# HC32F558 register map
File version: 1.0
CPU: CM4 r0p1, little endian, MPU, FPU, 4 interrupt priority bits
Registers are 32-bit, read-write, reset 0x0 unless marked. A register's access mark holds for its fields unless they carry their own. Offsets are from the block's base; [hi:lo] are bit positions; {n}, {i} and the like mark numbered series.

## CRC
Base 0x40008C00
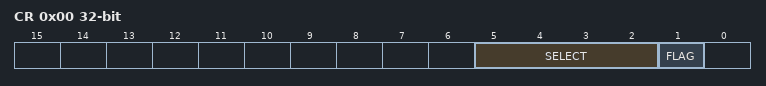
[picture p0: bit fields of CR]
0x00 CR
  [5:2] SELECT, [1] FLAG ro
0x04 RESLT
{0x80+4i} DAT{i} wo (i=0..31)

## CTC
Base 0x40049C00
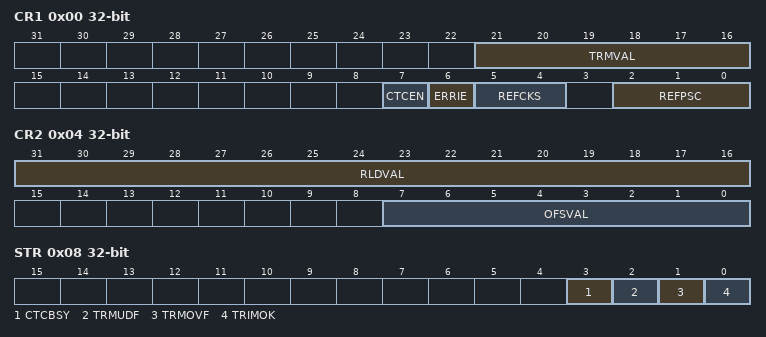
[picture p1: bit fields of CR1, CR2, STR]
0x00 CR1
  [21:16] TRMVAL, [7] CTCEN, [6] ERRIE, [5:4] REFCKS, [2:0] REFPSC
0x04 CR2
  [31:16] RLDVAL, [7:0] OFSVAL
0x08 STR ro
  [3] CTCBSY, [2] TRMUDF, [1] TRMOVF, [0] TRIMOK

## DAC1 — desc DAC
Base 0x40041000
Same registers: DAC2 0x40041400, DAC3 0x40041800, DAC4 0x40041C00
0x00 DADR1 16-bit
0x02 DADR2 16-bit
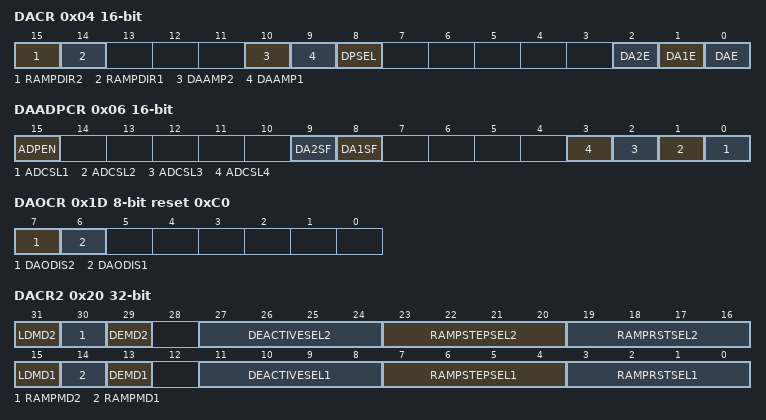
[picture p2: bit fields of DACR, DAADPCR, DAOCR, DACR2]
0x04 DACR 16-bit
  [15] RAMPDIR2, [14] RAMPDIR1, [10] DAAMP2, [9] DAAMP1, [8] DPSEL, [2] DA2E, [1] DA1E, [0] DAE
0x06 DAADPCR 16-bit
  [15] ADPEN, [9] DA2SF ro, [8] DA1SF ro, [n-1] ADCSL{n} (n=1..4)
0x1D DAOCR 8-bit reset 0xC0
  [7] DAODIS2, [6] DAODIS1
0x20 DACR2
  [31] LDMD2, [30] RAMPMD2, [29] DEMD2, [27:24] DEACTIVESEL2, [23:20] RAMPSTEPSEL2, [19:16] RAMPRSTSEL2, [15] LDMD1, [14] RAMPMD1, [13] DEMD1, [11:8] DEACTIVESEL1, [7:4] RAMPSTEPSEL1, [3:0] RAMPRSTSEL1
0x24 RAMPLMTR1 16-bit
  [11:0] RAMPLMT
0x26 RAMPLMTR2 16-bit
  [11:0] RAMPLMT
0x28 RAMPSTEPR1 16-bit
  [11:0] RAMPSTEP
0x2A RAMPSTEPR2 16-bit
  [11:0] RAMPSTEP
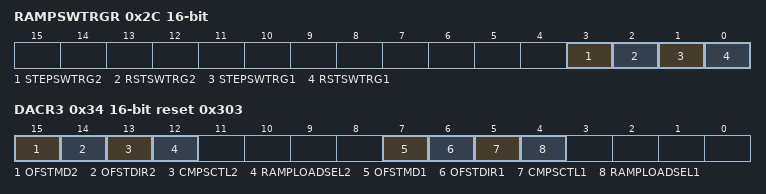
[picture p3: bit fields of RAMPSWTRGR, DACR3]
0x2C RAMPSWTRGR 16-bit wo
  [3] STEPSWTRG2, [2] RSTSWTRG2, [1] STEPSWTRG1, [0] RSTSWTRG1
0x30 DADACTR1 16-bit ro
  [11:0] DATAACT
0x32 DADACTR2 16-bit ro
  [11:0] DATAACT
0x34 DACR3 16-bit reset 0x303
  [15] OFSTMD2, [14] OFSTDIR2, [13] CMPSCTL2, [12] RAMPLOADSEL2, [7] OFSTMD1, [6] OFSTDIR1, [5] CMPSCTL1, [4] RAMPLOADSEL1
0x38 DADRDE1 16-bit
0x3A DADRDE2 16-bit
0x3C DADROF1 16-bit
0x3E DADROF2 16-bit
0x4C RAMPRSTDLYR1 16-bit
  [11:0] DARAMPRSTDLY
0x4E RAMPRSTDLYR2 16-bit
  [11:0] DARAMPRSTDLY
0x50 RAMPLMTACTR1 16-bit
  [11:0] RAMPLMTACT
0x52 RAMPLMTACTR2 16-bit
  [11:0] RAMPLMTACT
0x54 RAMPSTEPACTR1 16-bit
  [11:0] RAMPSTEPACT
0x56 RAMPSTEPACTR2 16-bit
  [11:0] RAMPSTEPACT
0x58 RAMPRSTDLYACTR1 16-bit
  [11:0] DARAMPRSTDLYACT
0x5A RAMPRSTDLYACTR2 16-bit
  [11:0] DARAMPRSTDLYACT

## DBGC
Base 0xE0042000
{0x0+4i} AUTHID{i} (i=0..2)
0x0C CHIPID ro reset 0x58480558
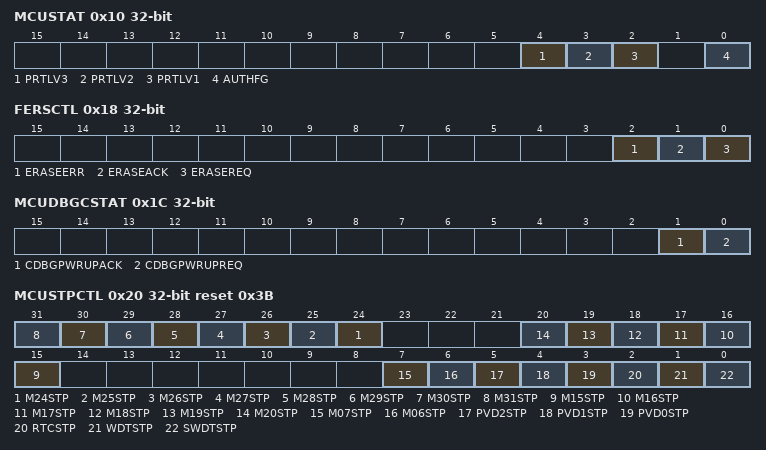
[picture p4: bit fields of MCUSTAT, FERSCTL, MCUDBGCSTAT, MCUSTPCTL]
0x10 MCUSTAT
  [4] PRTLV3, [3] PRTLV2, [2] PRTLV1, [0] AUTHFG
0x18 FERSCTL
  [2] ERASEERR, [1] ERASEACK, [0] ERASEREQ
0x1C MCUDBGCSTAT
  [1] CDBGPWRUPACK, [0] CDBGPWRUPREQ
0x20 MCUSTPCTL reset 0x3B (reset mask 0xFF1FF80FF)
  [n] M{n}STP (n=24..31), [n] M{n}STP (n=15..20), [7] M07STP, [6] M06STP, [5] PVD2STP, [4] PVD1STP, [3] PVD0STP, [2] RTCSTP, [1] WDTSTP, [0] SWDTSTP
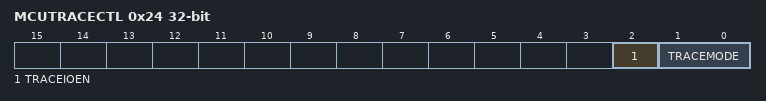
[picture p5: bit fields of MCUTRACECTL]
0x24 MCUTRACECTL
  [2] TRACEIOEN, [1:0] TRACEMODE

## DMA1 — desc DMA
Base 0x40053000
Same registers: DMA2 0x40053400
0x00 EN
  [0] EN
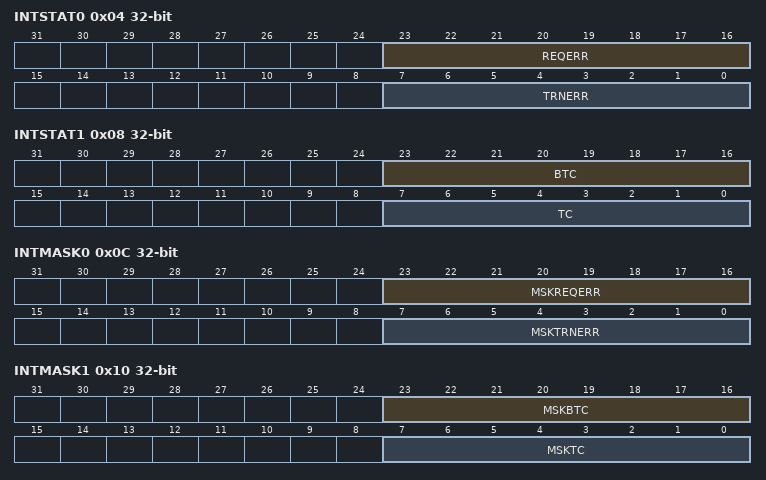
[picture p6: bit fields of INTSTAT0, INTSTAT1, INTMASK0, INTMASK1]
0x04 INTSTAT0 ro
  [23:16] REQERR, [7:0] TRNERR
0x08 INTSTAT1 ro
  [23:16] BTC, [7:0] TC
0x0C INTMASK0
  [23:16] MSKREQERR, [7:0] MSKTRNERR
0x10 INTMASK1
  [23:16] MSKBTC, [7:0] MSKTC
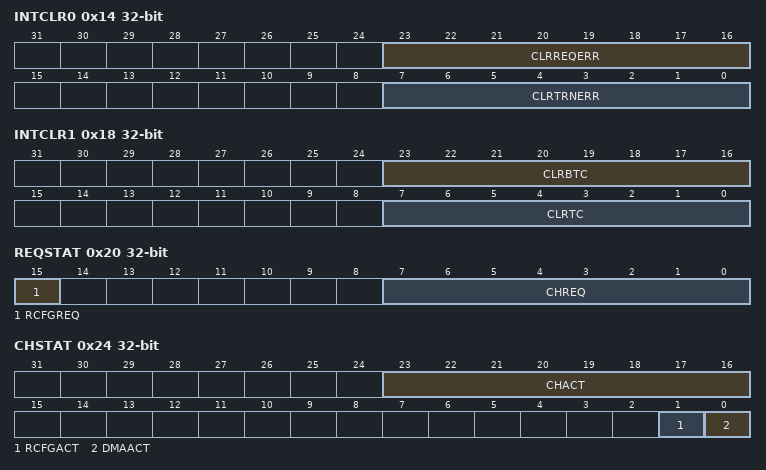
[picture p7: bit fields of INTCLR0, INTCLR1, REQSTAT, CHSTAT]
0x14 INTCLR0
  [23:16] CLRREQERR, [7:0] CLRTRNERR
0x18 INTCLR1
  [23:16] CLRBTC, [7:0] CLRTC
0x1C CHEN
  [7:0] CHEN
0x20 REQSTAT ro
  [15] RCFGREQ, [7:0] CHREQ
0x24 CHSTAT ro
  [23:16] CHACT, [1] RCFGACT, [0] DMAACT
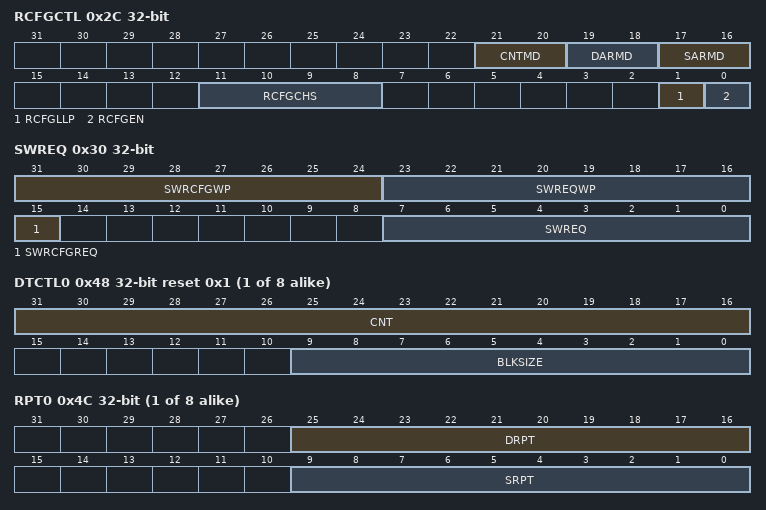
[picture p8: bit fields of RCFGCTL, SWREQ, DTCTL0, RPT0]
0x2C RCFGCTL
  [21:20] CNTMD, [19:18] DARMD, [17:16] SARMD, [11:8] RCFGCHS, [1] RCFGLLP, [0] RCFGEN
0x30 SWREQ wo
  [31:24] SWRCFGWP, [23:16] SWREQWP, [15] SWRCFGREQ, [7:0] SWREQ
0x34 CHENCLR wo
  [7:0] CHENCLR
{0x40+0x40*i} SAR{i} (i=0..7)
{0x44+0x40*i} DAR{i} (i=0..7)
{0x48+0x40*i} DTCTL{i} reset 0x1 (i=0..7)
  [31:16] CNT, [9:0] BLKSIZE
{0x4C+0x40*i} RPT{i} (i=0..7)
  [25:16] DRPT, [9:0] SRPT
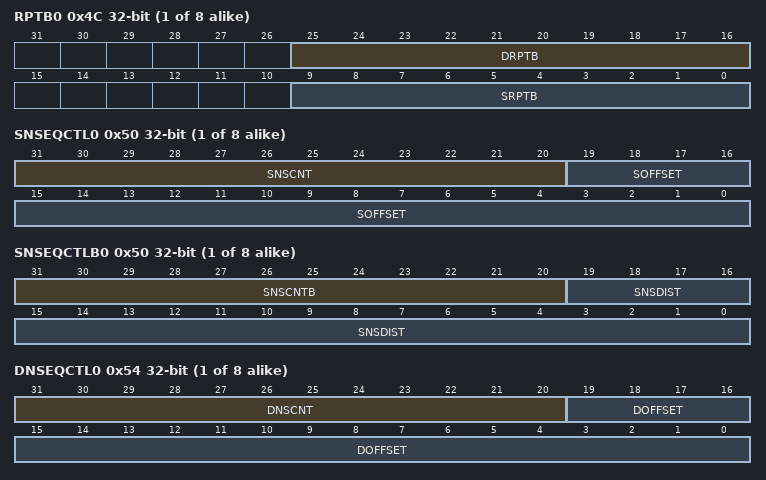
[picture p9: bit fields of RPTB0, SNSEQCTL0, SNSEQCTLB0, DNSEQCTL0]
{0x4C+0x40*i} RPTB{i} (alternate view of RPT{i}) (i=0..7)
  [25:16] DRPTB, [9:0] SRPTB
{0x50+0x40*i} SNSEQCTL{i} (i=0..7)
  [31:20] SNSCNT, [19:0] SOFFSET
{0x50+0x40*i} SNSEQCTLB{i} (alternate view of SNSEQCTL{i}) (i=0..7)
  [31:20] SNSCNTB, [19:0] SNSDIST
{0x54+0x40*i} DNSEQCTL{i} (i=0..7)
  [31:20] DNSCNT, [19:0] DOFFSET
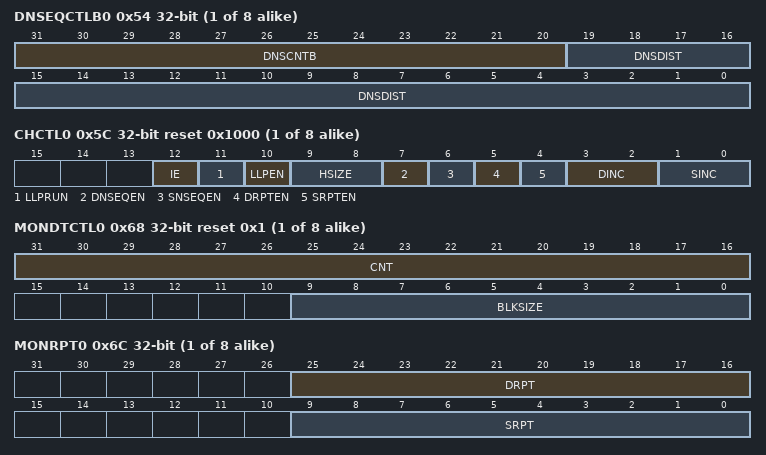
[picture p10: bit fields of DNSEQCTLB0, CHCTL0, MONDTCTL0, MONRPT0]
{0x54+0x40*i} DNSEQCTLB{i} (alternate view of DNSEQCTL{i}) (i=0..7)
  [31:20] DNSCNTB, [19:0] DNSDIST
{0x58+0x40*i} LLP{i} (i=0..7)
  [31:2] LLP
{0x5C+0x40*i} CHCTL{i} reset 0x1000 (i=0..7)
  [12] IE, [11] LLPRUN, [10] LLPEN, [9:8] HSIZE, [7] DNSEQEN, [6] SNSEQEN, [5] DRPTEN, [4] SRPTEN, [3:2] DINC, [1:0] SINC
{0x60+0x40*i} MONSAR{i} ro (i=0..7)
{0x64+0x40*i} MONDAR{i} ro (i=0..7)
{0x68+0x40*i} MONDTCTL{i} ro reset 0x1 (i=0..7)
  [31:16] CNT, [9:0] BLKSIZE
{0x6C+0x40*i} MONRPT{i} ro (i=0..7)
  [25:16] DRPT, [9:0] SRPT
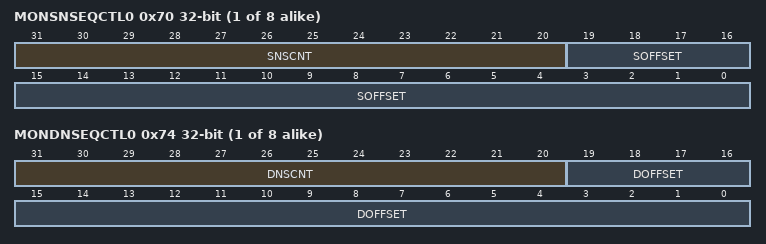
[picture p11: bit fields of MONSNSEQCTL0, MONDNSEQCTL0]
{0x70+0x40*i} MONSNSEQCTL{i} ro (i=0..7)
  [31:20] SNSCNT, [19:0] SOFFSET
{0x74+0x40*i} MONDNSEQCTL{i} ro (i=0..7)
  [31:20] DNSCNT, [19:0] DOFFSET
